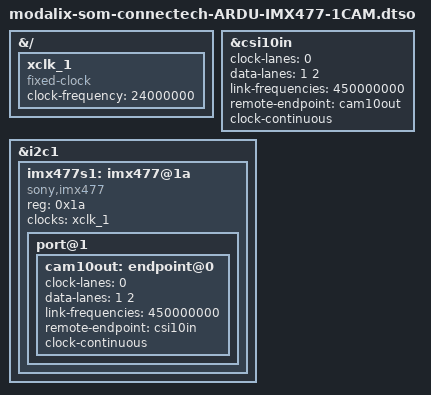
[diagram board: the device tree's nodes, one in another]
// SPDX-License-Identifier: (GPL-2.0+ OR MIT)
/*
 * Copyright (c) 2026 SiMa ai
 */

/dts-v1/;
/plugin/;

#include "modalix-som-connectech-1CAM.dtsi"

&{/} {
        xclk_1: xclk_1 {
                status = "okay";
                compatible = "fixed-clock";
                #clock-cells = <0>;
                clock-frequency = <24000000>;
        };
};

&csi10in {
    clock-lanes = <0>;
    data-lanes = <1 2>;
    link-frequencies = /bits/ 64 <450000000>;
    remote-endpoint = <&cam10out>;
    clock-continuous;
};

&i2c1 {
        imx477s1: imx477@1a {
                compatible = "sony,imx477";
                reg = <0x1a>;

                clocks = <&xclk_1>;
                clock-names = "xclk";

                port@1 {
                        cam10out: endpoint@0 {
                                clock-lanes = <0>;
                                data-lanes = <1 2>;
                                link-frequencies = /bits/ 64 <450000000>;
                                remote-endpoint = <&csi10in>;
                                clock-continuous;
                        };
                };
        };
};
